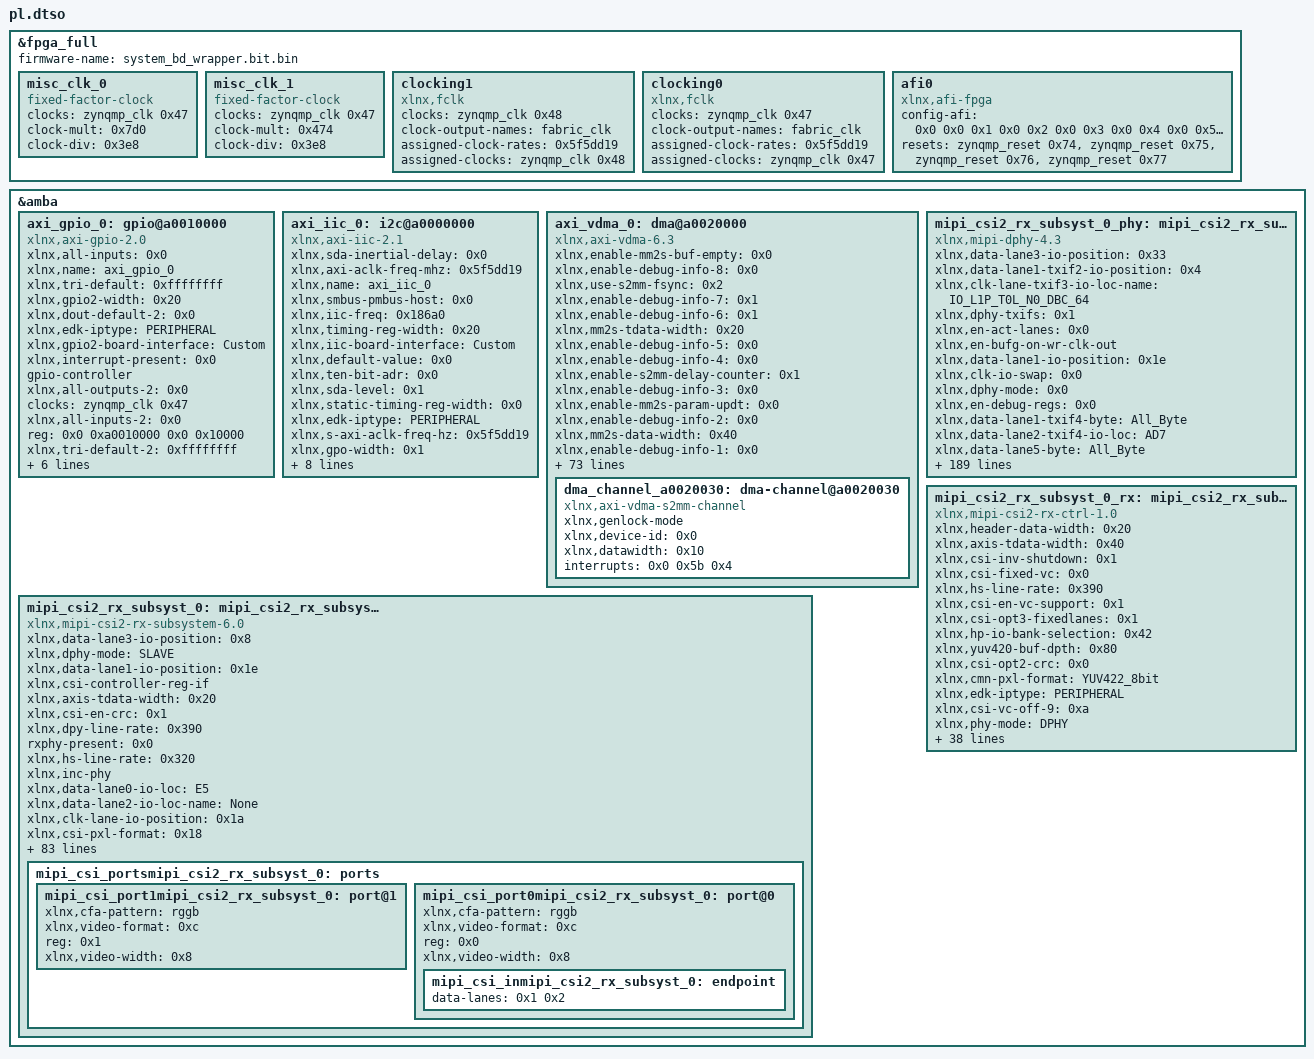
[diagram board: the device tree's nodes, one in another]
/dts-v1/;
/plugin/;

&fpga_full {
        firmware-name = "system_bd_wrapper.bit.bin";

        misc_clk_0: misc_clk_0 {
                #clock-cells = <0x0>;
                clocks = <&zynqmp_clk 0x47>;
                clock-mult = <0x7d0>;
                compatible = "fixed-factor-clock";
                clock-div = <0x3e8>;
        };

        misc_clk_1: misc_clk_1 {
                #clock-cells = <0x0>;
                clocks = <&zynqmp_clk 0x47>;
                clock-mult = <0x474>;
                compatible = "fixed-factor-clock";
                clock-div = <0x3e8>;
        };

        clocking1: clocking1 {
                clocks = <&zynqmp_clk 0x48>;
                clock-output-names = "fabric_clk";
                #clock-cells = <0x0>;
                assigned-clock-rates = <0x5f5dd19>;
                assigned-clocks = <&zynqmp_clk 0x48>;
                compatible = "xlnx,fclk";
        };

        clocking0: clocking0 {
                clocks = <&zynqmp_clk 0x47>;
                clock-output-names = "fabric_clk";
                #clock-cells = <0x0>;
                assigned-clock-rates = <0x5f5dd19>;
                assigned-clocks = <&zynqmp_clk 0x47>;
                compatible = "xlnx,fclk";
        };

        afi0: afi0 {
                config-afi = <0x0 0x0 0x1 0x0 0x2 0x0 0x3 0x0 0x4 0x0 0x5 0x0 0x6 0x0 0x7 0x0 0x8 0x0 0x9 0x0 0xa 0x0 0xb 0x0 0xc 0x0 0xd 0x0 0xe 0xa00 0xf 0x0>;
                resets = <&zynqmp_reset 0x74>,
                 <&zynqmp_reset 0x75>,
                 <&zynqmp_reset 0x76>,
                 <&zynqmp_reset 0x77>;
                compatible = "xlnx,afi-fpga";
        };
};

&amba {

        axi_gpio_0: gpio@a0010000 {
                xlnx,all-inputs = <0x0>;
                xlnx,name = "axi_gpio_0";
                xlnx,tri-default = <0xffffffff>;
                clock-names = "s_axi_aclk";
                xlnx,gpio2-width = <0x20>;
                xlnx,dout-default-2 = <0x0>;
                xlnx,edk-iptype = "PERIPHERAL";
                xlnx,gpio2-board-interface = "Custom";
                xlnx,interrupt-present = <0x0>;
                device_type = "gpio";
                gpio-controller;
                xlnx,all-outputs-2 = <0x0>;
                clocks = <&zynqmp_clk 0x47>;
                xlnx,all-inputs-2 = <0x0>;
                reg = <0x0 0xa0010000 0x0 0x10000>;
                xlnx,tri-default-2 = <0xffffffff>;
                xlnx,ip-name = "axi_gpio";
                xlnx,is-dual = <0x0>;
                xlnx,dout-default = <0x0>;
                xlnx,gpio-width = <0x1>;
                #gpio-cells = <0x2>;
                xlnx,all-outputs = <0x1>;
                compatible = "xlnx,axi-gpio-2.0", "xlnx,xps-gpio-1.00.a";
                xlnx,gpio-board-interface = "Custom";
        };

        axi_iic_0: i2c@a0000000 {
                xlnx,sda-inertial-delay = <0x0>;
                xlnx,axi-aclk-freq-mhz = <0x5f5dd19>;
                xlnx,name = "axi_iic_0";
                xlnx,smbus-pmbus-host = <0x0>;
                xlnx,iic-freq = <0x186a0>;
                xlnx,timing-reg-width = <0x20>;
                xlnx,iic-board-interface = "Custom";
                interrupt-names = "iic2intc_irpt";
                xlnx,default-value = <0x0>;
                xlnx,ten-bit-adr = <0x0>;
                clock-names = "s_axi_aclk";
                xlnx,sda-level = <0x1>;
                xlnx,static-timing-reg-width = <0x0>;
                xlnx,edk-iptype = "PERIPHERAL";
                xlnx,s-axi-aclk-freq-hz = <0x5f5dd19>;
                xlnx,gpo-width = <0x1>;
                clocks = <&zynqmp_clk 0x47>;
                reg = <0x0 0xa0000000 0x0 0x10000>;
                xlnx,disable-setup-violation-check = <0x0>;
                xlnx,ip-name = "axi_iic";
                interrupt-parent = <&gic>;
                xlnx,scl-inertial-delay = <0x0>;
                compatible = "xlnx,axi-iic-2.1", "xlnx,xps-iic-2.00.a";
                xlnx,iic-freq-khz = <0x64>;
                interrupts = <0x0 0x59 0x4>;
        };

        axi_vdma_0: dma@a0020000 {
                xlnx,enable-mm2s-buf-empty = <0x0>;
                xlnx,enable-debug-info-8 = <0x0>;
                xlnx,use-s2mm-fsync = <0x2>;
                xlnx,enable-debug-info-7 = <0x1>;
                xlnx,enable-debug-info-6 = <0x1>;
                xlnx,mm2s-tdata-width = <0x20>;
                xlnx,enable-debug-info-5 = <0x0>;
                xlnx,enable-debug-info-4 = <0x0>;
                xlnx,enable-s2mm-delay-counter = <0x1>;
                xlnx,enable-debug-info-3 = <0x0>;
                xlnx,enable-mm2s-param-updt = <0x0>;
                xlnx,enable-debug-info-2 = <0x0>;
                xlnx,mm2s-data-width = <0x40>;
                xlnx,enable-debug-info-1 = <0x0>;
                xlnx,enable-debug-all = <0x0>;
                xlnx,enable-debug-info-0 = <0x0>;
                xlnx,mm2s-genlock-mode = <0x0>;
                xlnx,enable-vidprmtr-reads = <0x1>;
                #dma-cells = <0x1>;
                xlnx,s2mm-tdata-width = <0x10>;
                xlnx,prmry-is-aclk-async = <0x0>;
                xlnx,mm2s-genlock-repeat-en = <0x0>;
                xlnx,enable-vidparam-reads = <0x1>;
                xlnx,enable-s2mm-param-updt = <0x0>;
                xlnx,num-fstores = <0x3>;
                xlnx,s2mm-data-width = <0x80>;
                xlnx,select-xpm = <0x0>;
                xlnx,flush-fsync = <0x1>;
                xlnx,s2mm-genlock-mode = <0x2>;
                xlnx,include-mm2s = <0x0>;
                xlnx,mm2s-linebuffer-depth = <0x200>;
                xlnx,enable-debug-info-15 = <0x1>;
                clock-names = "m_axi_s2mm_aclk", "s_axi_lite_aclk", "s_axis_s2mm_aclk";
                xlnx,include-internal-genlock = <0x1>;
                xlnx,enable-debug-info-14 = <0x1>;
                xlnx,include-mm2s-sf = <0x0>;
                xlnx,enable-vert-flip = <0x0>;
                xlnx,enable-debug-info-13 = <0x0>;
                xlnx,s2mm-genlock-repeat-en = <0x1>;
                xlnx,use-fsync = <0x1>;
                xlnx,enable-debug-info-12 = <0x0>;
                xlnx,edk-iptype = "PERIPHERAL";
                xlnx,enable-debug-info-11 = <0x0>;
                xlnx,addrwidth = <0x20>;
                xlnx,enable-debug-info-10 = <0x0>;
                xlnx,s-axis-s2mm-tdata-width = <0x10>;
                clocks = <&misc_clk_0>,
                 <&zynqmp_clk 0x47>,
                 <&misc_clk_0>;
                xlnx,addr-width = <0x20>;
                xlnx,include-s2mm = <0x1>;
                xlnx,s2mm-linebuffer-depth = <0x200>;
                xlnx,single-interface = <0x0>;
                xlnx,include-s2mm-sf = <0x1>;
                xlnx,flush-on-fsync = <0x1>;
                xlnx,m-axi-mm2s-data-width = <0x40>;
                interrupts = <0x0 0x5b 0x4>;
                xlnx,enable-mm2s-frmstr-reg = <0x0>;
                xlnx,name = "axi_vdma_0";
                xlnx,include-mm2s-dre = <0x0>;
                xlnx,mm2s-max-burst-length = <0x8>;
                xlnx,enable-s2mm-sts-reg = <0x0>;
                xlnx,m-axi-s2mm-data-width = <0x80>;
                xlnx,enable-s2mm-frmstr-reg = <0x0>;
                xlnx,include-s2mm-dre = <0x0>;
                xlnx,mm2s-sof-enable = <0x1>;
                xlnx,enable-mm2s-rst-out = <0x0>;
                xlnx,s2mm-max-burst-length = <0x8>;
                interrupt-parent = <&gic>;
                xlnx,enable-tstvec = <0x0>;
                compatible = "xlnx,axi-vdma-6.3", "xlnx,axi-vdma-1.00.a";
                xlnx,mm2s-linebuffer-thresh = <0x4>;
                xlnx,enable-mm2s-fsync-out = <0x0>;
                xlnx,mm2s-genlock-num-masters = <0x1>;
                xlnx,s2mm-sof-enable = <0x1>;
                interrupt-names = "s2mm_introut";
                xlnx,enable-s2mm-rst-out = <0x0>;
                xlnx,dynamic-resolution = <0x1>;
                xlnx,enable-all = <0x0>;
                xlnx,m-axis-mm2s-tdata-width = <0x20>;
                xlnx,enable-mm2s-frm-counter = <0x1>;
                xlnx,s2mm-linebuffer-thresh = <0x4>;
                xlnx,use-mm2s-fsync = <0x0>;
                xlnx,enable-s2mm-fsync-out = <0x0>;
                reg = <0x0 0xa0020000 0x0 0x10000>;
                xlnx,s2mm-genlock-num-masters = <0x1>;
                xlnx,ip-name = "axi_vdma";
                xlnx,enable-s2mm-buf-full = <0x0>;
                xlnx,dlytmr-resolution = <0x7d>;
                xlnx,enable-mm2s-delay-counter = <0x1>;
                xlnx,enable-s2mm-frm-counter = <0x1>;
                xlnx,enable-debug-info-9 = <0x0>;

                dma_channel_a0020030: dma-channel@a0020030 {
                        xlnx,genlock-mode;
                        compatible = "xlnx,axi-vdma-s2mm-channel";
                        xlnx,device-id = <0x0>;
                        xlnx,datawidth = <0x10>;
                        interrupts = <0x0 0x5b 0x4>;
                };
        };

        mipi_csi2_rx_subsyst_0: mipi_csi2_rx_subsystem@a0030000 {
                xlnx,data-lane3-io-position = <0x8>;
                xlnx,dphy-mode = "SLAVE";
                xlnx,data-lane1-io-position = <0x1e>;
                xlnx,csi-controller-reg-if;
                xlnx,axis-tdata-width = <0x20>;
                xlnx,csi-en-crc = <0x1>;
                xlnx,dpy-line-rate = <0x390>;
                rxphy-present = <0x0>;
                xlnx,hs-line-rate = <0x320>;
                xlnx,inc-phy;
                xlnx,data-lane0-io-loc = "E5";
                xlnx,data-lane2-io-loc-name = "None";
                xlnx,clk-lane-io-position = <0x1a>;
                xlnx,csi-pxl-format = <0x18>;
                xlnx,data-lane0-io-loc-name = "IO_L14P_T2L_N2_GC_66";
                xlnx,dphy-preset = "CSI2RX_XLNX";
                xlnx,exdesboard-version = <0x2>;
                xlnx,exdes-config = "MIPI_Video_Pipe_Camera_to_Display";
                xlnx,cmn-num-lanes = <0x2>;
                xlnx,enable-shim-flop = <0x0>;
                xlnx,highaddr = <0xa0031fff>;
                csirx-connected = <&mipi_csi2_rx_subsyst_0_rx>;
                xlnx,lprx-disable-extport = <0x0>;
                xlnx,idly-group-name = "mipi_csi2rx_idly_group";
                xlnx,hp-io-bank-selection = <0x42>;
                xlnx,yuv420-buf-dpth = <0x80>;
                csirx-present = <0x1>;
                xlnx,ooc-vid-clk = <0x65b710>;
                xlnx,data-lane0-byte = "All_Byte";
                xlnx,data-lane1-io-loc = "G6";
                clock-names = "dphy_clk_200M", "lite_aclk", "video_aclk";
                xlnx,int-qor-check = <0x0>;
                xlnx,cmn-pxl-format = <0x18>;
                xlnx,init = <0x186a0>;
                xlnx,edk-iptype = "PERIPHERAL";
                xlnx,en-csi-v2 = <0x0>;
                xlnx,axis-tdest-width = <0x4>;
                xlnx,phy-mode = "DPHY";
                xlnx,stretch-line-rate = <0x1194>;
                xlnx,data-lane3-byte = "All_Byte";
                xlnx,cmn-fifo-rd-en-cntrl;
                xlnx,mipi-slv-int = <0x0>;
                xlnx,data-lane2-io-loc = "None";
                clocks = <&misc_clk_0>,
                 <&zynqmp_clk 0x47>,
                 <&misc_clk_0>;
                xlnx,io-type = <0x0>;
                xlnx,hs-settle-ns = <0x91>;
                xlnx,clock-mask = <0x25>;
                xlnx,data-lane3-io-loc = "None";
                xlnx,dphyrx-board-interface = "som240_1_connector_mipi_csi_raspi";
                interrupts = <0x0 0x5a 0x4>;
                xlnx,csi-emb-non-img = <0x0>;
                xlnx,name = "mipi_csi2_rx_subsyst_0";
                xlnx,en-vcx = <0x0>;
                xlnx,vc = <0x4>;
                xlnx,data-lane2-io-position = <0x6>;
                xlnx,exdes-board = "ZCU102";
                xlnx,data-lane0-io-position = <0x1c>;
                xlnx,mipi-rx-phy-mode = <0x1>;
                xlnx,cal-mode = "NONE";
                xlnx,master-riu;
                xlnx,data-lane1-byte = "All_Byte";
                xlnx,ext-mmcm = <0x0>;
                xlnx,data-lane3-io-loc-name = "None";
                xlnx,hs-timeout = <0x10005>;
                dphy-connected = <&mipi_csi2_rx_subsyst_0_phy>;
                xlnx,data-lane1-io-loc-name = "IO_L15P_T2L_N4_AD11P_66";
                interrupt-parent = <&gic>;
                xlnx,vfb;
                xlnx,fifo-rd-en-control;
                xlnx,csi2rx-dbg = <0x0>;
                xlnx,cmn-proj-family = <0x1>;
                xlnx,cmn-num-pixels = <0x1>;
                dphy-present = <0x1>;
                xlnx,idly-tap = <0x1>;
                compatible = "xlnx,mipi-csi2-rx-subsystem-6.0", "xlnx,mipi-csi2-rx-subsystem-5.0";
                xlnx,axis-tuser-width = <0x60>;
                xlnx,cmn-inc-vfb;
                interrupt-names = "csirxss_csi_irq";
                xlnx,esc-timeout = <0x6400>;
                xlnx,clk-lane-io-loc = "D7";
                xlnx,max-lanes = <0x2>;
                xlnx,clk-lane-io-loc-name = "IO_L13P_T2L_N0_GC_QBC_66";
                xlnx,supportlevel = <0x1>;
                xlnx,exdes-fmc = "LI-IMX274MIPI-FMC , V1.0 , Single , Sensor";
                xlnx,csi-buf-depth = <0x800>;
                xlnx,ppc = <0x1>;
                xlnx,vfb-tu-width = <0x1>;
                reg = <0x0 0xa0030000 0x0 0x2000>;
                xlnx,ip-name = "mipi_csi2_rx_subsystem";
                xlnx,dphy-lanes = <0x2>;
                xlnx,cmn-vc = <0x4>;
                xlnx,dpy-en-reg-if = <0x1>;
                xlnx,data-lane2-byte = "All_Byte";

                mipi_csi_portsmipi_csi2_rx_subsyst_0: ports {
                        #size-cells = <0x0>;
                        #address-cells = <0x1>;

                        mipi_csi_port1mipi_csi2_rx_subsyst_0: port@1 {
                                xlnx,cfa-pattern = "rggb";
                                xlnx,video-format = <0xc>;
                                reg = <0x1>;
                                xlnx,video-width = <0x8>;
                        };

                        mipi_csi_port0mipi_csi2_rx_subsyst_0: port@0 {
                                xlnx,cfa-pattern = "rggb";
                                xlnx,video-format = <0xc>;
                                reg = <0x0>;
                                xlnx,video-width = <0x8>;

                                mipi_csi_inmipi_csi2_rx_subsyst_0: endpoint {
                                        data-lanes = <0x1 0x2>;
                                };
                        };
                };
        };

        mipi_csi2_rx_subsyst_0_phy: mipi_csi2_rx_subsyst_0_phy@1000 {
                xlnx,data-lane3-io-position = <0x33>;
                xlnx,data-lane1-txif2-io-position = <0x4>;
                xlnx,clk-lane-txif3-io-loc-name = "IO_L1P_T0L_N0_DBC_64";
                xlnx,dphy-txifs = <0x1>;
                xlnx,en-act-lanes = <0x0>;
                xlnx,en-bufg-on-wr-clk-out;
                xlnx,data-lane1-io-position = <0x1e>;
                xlnx,clk-io-swap = <0x0>;
                xlnx,dphy-mode = <0x0>;
                xlnx,en-debug-regs = <0x0>;
                xlnx,data-lane1-txif4-byte = "All_Byte";
                xlnx,data-lane2-txif4-io-loc = "AD7";
                xlnx,data-lane5-byte = "All_Byte";
                xlnx,dbg-ports-on = <0x0>;
                xlnx,tx-riu-wr-gap = <0x12>;
                xlnx,data-lane3-txif4-io-loc-name = "IO_L5P_T0U_N8_AD14P_64";
                xlnx,txif3-hp-io-bank-selection = <0x40>;
                xlnx,s50-logic = <0x0>;
                xlnx,data-lane0-txif3-byte = "All_Byte";
                xlnx,data-lane6-io-loc-name = "None";
                xlnx,pll-clkoutphy-mode = "VCO";
                xlnx,skewcal-periodic-time = <0x80>;
                xlnx,data-lane3-txif2-io-loc-name = "IO_L5P_T0U_N8_AD14P_64";
                xlnx,hs-line-rate = <0x390>;
                xlnx,data-lane0-txif2-io-loc = "AE9";
                xlnx,data-lane1-txif3-io-loc-name = "IO_L3P_T0L_N4_AD15P_64";
                xlnx,data-lane4-io-loc-name = "None";
                xlnx,data-lane0-io-loc = "E5";
                xlnx,data-lane2-io-loc-name = "None";
                xlnx,div4-clk-period = <0x85d9a0>;
                xlnx,clk-lane-io-position = <0x1a>;
                xlnx,en-timeout-regs = <0x0>;
                xlnx,data-lane0-io-loc-name = "IO_L14P_T2L_N2_GC_66";
                xlnx,dphy-preset = "CSI2RX_XLNX";
                xlnx,data-lane3-txif2-io-loc = "AB7";
                xlnx,dphytx-board-interface = "Custom";
                xlnx,data-lane2-txif3-io-position = <0x33>;
                xlnx,enable-shim-flop = <0x0>;
                xlnx,highaddr = <0x1fff>;
                xlnx,data-lane0-txif4-io-position = <0x2>;
                xlnx,esc-clk-period = <0x32>;
                xlnx,idly-group-name = "mipi_csi2rx_idly_group";
                xlnx,lprx-disable-extport = <0x0>;
                xlnx,data-lane0-txif3-io-loc = "AE9";
                xlnx,pll-divclk-mult = <0x8>;
                xlnx,hp-io-bank-selection = <0x42>;
                xlnx,data-lane0-txif2-io-position = <0x2>;
                xlnx,data-lane0-byte = "All_Byte";
                xlnx,data-lane1-io-loc = "G6";
                xlnx,en-hs-obuftds = <0x0>;
                xlnx,data-lane3-txif4-byte = "All_Byte";
                clock-names = "core_clk", "s_axi_aclk";
                xlnx,data-lane2-txif3-byte = "All_Byte";
                xlnx,data-lane3-txif3-io-loc = "AB7";
                xlnx,init = <0x186a0>;
                xlnx,edk-iptype = "PERIPHERAL";
                xlnx,stretch-line-rate = <0x1194>;
                xlnx,data-lane0-txif4-io-loc = "AE9";
                xlnx,data-lane1-txif2-byte = "All_Byte";
                xlnx,data-lane2-txif4-io-loc-name = "IO_L4P_T0U_N6_DBC_AD7P_64";
                xlnx,data-lane3-byte = "All_Byte";
                xlnx,en-clk300m = <0x0>;
                xlnx,stable-clk-period = <0x5>;
                xlnx,clk-lane-txif3-io-position = <0x0>;
                xlnx,en-ssc = <0x0>;
                xlnx,data-lane2-io-loc = "None";
                xlnx,data-lane2-txif2-io-loc-name = "IO_L4P_T0U_N6_DBC_AD7P_64";
                xlnx,xiphy-line-rate-min = <0x258>;
                clocks = <&misc_clk_0>,
                 <&zynqmp_clk 0x47>;
                xlnx,data-lane0-txif3-io-loc-name = "IO_L2P_T0L_N2_64";
                xlnx,is-hierarchy;
                xlnx,hs-settle-ns = <0x91>;
                xlnx,io-type = <0x0>;
                xlnx,data-lane3-txif4-io-loc = "AB7";
                xlnx,data-lane6-byte = "All_Byte";
                xlnx,data-lane3-txif4-io-position = <0x33>;
                xlnx,txif4-hp-io-bank-selection = <0x40>;
                xlnx,data-lane6-io-position = <0x33>;
                xlnx,data-lane0-txif4-byte = "All_Byte";
                xlnx,data-lane3-txif2-io-position = <0x33>;
                xlnx,txif1-createinst;
                xlnx,txif4-instname = "tx64";
                xlnx,data-lane4-io-position = <0x33>;
                xlnx,data-lane1-txif3-io-position = <0x4>;
                xlnx,data-lane1-txif2-io-loc = "AB8";
                xlnx,data-lane3-io-loc = "None";
                xlnx,dphyrx-board-interface = "som240_1_connector_mipi_csi_raspi";
                xlnx,clk-lane-txif4-io-loc-name = "IO_L1P_T0L_N0_DBC_64";
                xlnx,name = "mipi_csi2_rx_subsyst_0_phy";
                xlnx,pll-clk0-divide = <0x8>;
                xlnx,data-lane2-io-position = <0x33>;
                xlnx,clk-lane-txif2-io-loc-name = "IO_L1P_T0L_N0_DBC_64";
                xlnx,en-txsplt = <0x0>;
                xlnx,data-lane0-io-position = <0x1c>;
                xlnx,versal = <0x0>;
                xlnx,wakeup = <0xf4240>;
                xlnx,data-lane3-txif2-byte = "All_Byte";
                xlnx,dl7-io-swap = <0x0>;
                xlnx,data-lane7-io-loc-name = "None";
                xlnx,dl6-io-swap = <0x0>;
                xlnx,use-lane0-txreadyhs;
                xlnx,data-lane1-txif3-io-loc = "AB8";
                xlnx,data-lane3-txif3-io-loc-name = "IO_L5P_T0U_N8_AD14P_64";
                xlnx,data-lane4-io-loc = "None";
                xlnx,dl5-io-swap = <0x0>;
                xlnx,cal-mode = "FIXED";
                xlnx,pll-clk1-divide = <0x8>;
                xlnx,txif3-instname = "tx64";
                xlnx,data-lane1-txif4-io-loc-name = "IO_L3P_T0L_N4_AD15P_64";
                xlnx,data-lane5-io-loc-name = "None";
                xlnx,dl4-io-swap = <0x0>;
                xlnx,master-riu;
                xlnx,data-lane1-byte = "All_Byte";
                xlnx,dl3-io-swap = <0x0>;
                xlnx,data-lane1-txif2-io-loc-name = "IO_L3P_T0L_N4_AD15P_64";
                xlnx,data-lane3-io-loc-name = "None";
                xlnx,txif4-hp-io-bank-name = "64_(HP)";
                xlnx,dl2-io-swap = <0x0>;
                xlnx,hs-timeout = <0x10005>;
                xlnx,mtbf-sync-stages = <0x3>;
                xlnx,txif3-hp-io-bank-name = "64_(HP)";
                xlnx,xsdb-intf-en = <0x0>;
                xlnx,dl1-io-swap = <0x0>;
                xlnx,example-simulation = <0x1>;
                xlnx,data-lane1-io-loc-name = "IO_L15P_T2L_N4_AD11P_66";
                xlnx,data-lane2-txif4-byte = "All_Byte";
                xlnx,txif2-hp-io-bank-name = "64_(HP)";
                xlnx,dl0-io-swap = <0x0>;
                xlnx,fifo-rd-en-control;
                xlnx,data-lane2-txif4-io-position = <0x33>;
                xlnx,idly-tap = <0x0>;
                xlnx,data-lane1-txif3-byte = "All_Byte";
                xlnx,data-lane1-txif4-io-loc = "AB8";
                xlnx,data-lane4-byte = "All_Byte";
                xlnx,data-lane5-io-loc = "None";
                xlnx,en-rxppi-as-mon = <0x0>;
                xlnx,txif2-hp-io-bank-selection = <0x40>;
                xlnx,data-lane2-txif2-io-position = <0x33>;
                compatible = "xlnx,mipi-dphy-4.3";
                xlnx,en-reg-if = <0x1>;
                xlnx,txpll-clkin-period = <0x85d9a0>;
                xlnx,data-lane0-txif2-byte = "All_Byte";
                xlnx,ddr-clk-period = <0x217280>;
                xlnx,data-lane0-txif3-io-position = <0x2>;
                xlnx,clk-lane-txif2-io-loc = "AC9";
                xlnx,txif2-instname = "tx64";
                xlnx,en-debug-tx-calib = <0x0>;
                xlnx,clk-lane-io-loc = "D7";
                xlnx,esc-timeout = <0x6400>;
                xlnx,data-lane7-byte = "All_Byte";
                xlnx,clk-lane-io-loc-name = "IO_L13P_T2L_N0_GC_QBC_66";
                xlnx,rx-equalization = "EQ_LEVEL4";
                xlnx,tx-output-impedance;
                xlnx,data-lane6-io-loc = "None";
                xlnx,supportlevel;
                xlnx,pll-divclk-divide = <0x1>;
                xlnx,en-ext-tap = <0x0>;
                xlnx,data-lane2-txif2-io-loc = "AD7";
                xlnx,clk-lane-txif4-io-position = <0x0>;
                xlnx,clk-lane-txif3-io-loc = "AC9";
                xlnx,data-lane2-txif3-io-loc-name = "IO_L4P_T0U_N6_DBC_AD7P_64";
                xlnx,en-dcts-logic = <0x0>;
                xlnx,en-io-sel = <0x1>;
                xlnx,data-lane0-txif4-io-loc-name = "IO_L2P_T0L_N2_64";
                xlnx,clk-lane-txif2-io-position = <0x0>;
                reg = <0x0 0xa0031000 0x0 0x1000>;
                xlnx,txif1-instname = "tx66";
                xlnx,ip-name = "mipi_dphy";
                xlnx,data-lane0-txif2-io-loc-name = "IO_L2P_T0L_N2_64";
                xlnx,data-lane3-txif3-byte = "All_Byte";
                xlnx,data-lane7-io-loc = "None";
                xlnx,data-lane7-io-position = <0x33>;
                xlnx,dphy-lanes = <0x2>;
                xlnx,en-txcalib-sim = <0x0>;
                xlnx,data-lane3-txif3-io-position = <0x33>;
                xlnx,en-tx-algo = <0x0>;
                xlnx,lpx-period = <0x32>;
                xlnx,data-lane2-txif2-byte = "All_Byte";
                xlnx,data-lane2-txif3-io-loc = "AD7";
                xlnx,hp-io-bank-name = "66_(HP)_(Half , Bank)";
                xlnx,data-lane5-io-position = <0x33>;
                xlnx,data-lane1-txif4-io-position = <0x4>;
                xlnx,clk-lane-txif4-io-loc = "AC9";
                xlnx,skewcal-first-time = <0x1000>;
                xlnx,en-dphy-io = <0x1>;
                xlnx,data-lane2-byte = "All_Byte";
        };

        mipi_csi2_rx_subsyst_0_rx: mipi_csi2_rx_subsyst_0_rx@0 {
                xlnx,header-data-width = <0x20>;
                xlnx,axis-tdata-width = <0x40>;
                xlnx,csi-inv-shutdown = <0x1>;
                xlnx,csi-fixed-vc = <0x0>;
                xlnx,hs-line-rate = <0x390>;
                xlnx,csi-en-vc-support = <0x1>;
                xlnx,csi-opt3-fixedlanes = <0x1>;
                xlnx,hp-io-bank-selection = <0x42>;
                xlnx,yuv420-buf-dpth = <0x80>;
                clock-names = "core_clk", "dl0_rxbyteclkhs", "dl1_rxbyteclkhs", "m_axis_aclk", "s_axi_aclk", "video_aclk";
                xlnx,csi-opt2-crc = <0x0>;
                xlnx,cmn-pxl-format = "YUV422_8bit";
                xlnx,edk-iptype = "PERIPHERAL";
                xlnx,csi-vc-off-9 = <0xa>;
                xlnx,phy-mode = "DPHY";
                xlnx,axis-tdest-width = <0x4>;
                xlnx,csi-vc-off-8 = <0x9>;
                xlnx,csi-vc-off-7 = <0x8>;
                xlnx,mipi-slv-int = <0x0>;
                xlnx,axis-fifo-dcnt-width = <0xb>;
                clocks = <&misc_clk_0>,
                 <&misc_clk_1>,
                 <&misc_clk_1>,
                 <&misc_clk_0>,
                 <&zynqmp_clk 0x47>,
                 <&misc_clk_0>;
                xlnx,csi-vc-off-6 = <0x7>;
                xlnx,axis-fifo-depth = <0x800>;
                xlnx,is-hierarchy;
                xlnx,csi-vc-off-5 = <0x6>;
                xlnx,csi-lanes = <0x2>;
                xlnx,csi-vc-off-4 = <0x5>;
                xlnx,csi-vc-off-3 = <0x4>;
                xlnx,csi-vc-off-2 = <0x3>;
                xlnx,csi-vc-off-1 = <0x2>;
                xlnx,csi-vc-off-0 = <0x1>;
                xlnx,name = "mipi_csi2_rx_subsyst_0_rx";
                xlnx,ppi-mult = <0x0>;
                xlnx,csi-vc-off-14 = <0xf>;
                xlnx,csi-vc-off-13 = <0xe>;
                xlnx,csi-vc-off-12 = <0xd>;
                xlnx,csi-vc-off-11 = <0xc>;
                xlnx,emb-dw = <0x40>;
                xlnx,csi-vc-off-10 = <0xb>;
                xlnx,csi-offload-nonimage = <0x0>;
                xlnx,csi-filter-userdatatype = <0x0>;
                xlnx,ppi-sync-width = <0x0>;
                xlnx,disable-lite = <0x0>;
                xlnx,csi-opt1-regs = <0x0>;
                xlnx,csi2rx-dbg = <0x0>;
                xlnx,cmn-proj-family = <0x0>;
                xlnx,cmn-num-pixels = <0x1>;
                compatible = "xlnx,mipi-csi2-rx-ctrl-1.0";
                xlnx,axis-tuser-width = <0x60>;
                xlnx,cmn-inc-vfb;
                xlnx,ppi-sig-width = <0x0>;
                reg = <0x0 0xa0030000 0x0 0x1000>;
                xlnx,ip-name = "mipi_csi2_rx_ctrl";
        };
};

